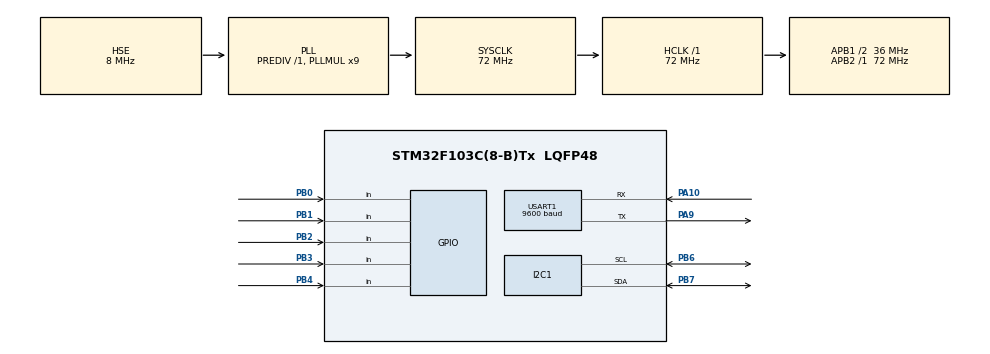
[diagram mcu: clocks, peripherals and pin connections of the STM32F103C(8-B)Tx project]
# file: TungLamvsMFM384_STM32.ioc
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FREERTOS.Mutexes01=mMeter,Dynamic,NULL,Available
FREERTOS.Queues01=qMeter,8,uint8_t,0,Dynamic,NULL,NULL
FREERTOS.Tasks01=rs485Task,1,768,StartDefaultTask,Default,NULL,Dynamic,NULL,NULL;touTask,0,512,StartTask02,Default,NULL,Dynamic,NULL,NULL;lcdTask,0,384,StartTask03,Default,NULL,Dynamic,NULL,NULL;uiTask,-2,384,StartTask04,Default,NULL,Dynamic,NULL,NULL;wdgTask,2,256,StartTask05,Default,NULL,Dynamic,NULL,NULL
FREERTOS.configTOTAL_HEAP_SIZE=20480
IWDG.Prescaler=IWDG_PRESCALER_64
IWDG.Reload=1250
Mcu.Family=STM32F1
Mcu.Name=STM32F103C(8-B)Tx
Mcu.Package=LQFP48
NVIC.PriorityGroup=NVIC_PRIORITYGROUP_4
NVIC.USART1_IRQn=true\:5\:0\:false\:false\:true\:true\:true\:true\:true
PA10.Mode=Asynchronous
PA10.Signal=USART1_RX
PA13.Mode=Serial_Wire
PA13.Signal=SYS_JTMS-SWDIO
PA14.Mode=Serial_Wire
PA14.Signal=SYS_JTCK-SWCLK
PA9.Mode=Asynchronous
PA9.Signal=USART1_TX
PB0.Signal=GPIO_Input
PB1.Signal=GPIO_Input
PB2.Signal=GPIO_Input
PB3.Signal=GPIO_Input
PB4.Signal=GPIO_Input
PB6.Mode=I2C
PB6.Signal=I2C1_SCL
PB7.Mode=I2C
PB7.Signal=I2C1_SDA
PC14-OSC32_IN.Mode=LSE-External-Oscillator
PC14-OSC32_IN.Signal=RCC_OSC32_IN
PC15-OSC32_OUT.Mode=LSE-External-Oscillator
PC15-OSC32_OUT.Signal=RCC_OSC32_OUT
PD0-OSC_IN.Mode=HSE-External-Oscillator
PD0-OSC_IN.Signal=RCC_OSC_IN
PD1-OSC_OUT.Mode=HSE-External-Oscillator
PD1-OSC_OUT.Signal=RCC_OSC_OUT
ProjectManager.HeapSize=0x200
ProjectManager.StackSize=0x400
ProjectManager.TargetToolchain=MDK-ARM V5.32
RCC.AHBFreq_Value=72000000
RCC.APB1CLKDivider=RCC_HCLK_DIV2
RCC.APB1Freq_Value=36000000
RCC.APB1TimFreq_Value=72000000
RCC.APB2Freq_Value=72000000
RCC.APB2TimFreq_Value=72000000
RCC.HCLKFreq_Value=72000000
RCC.PLLMUL=RCC_PLL_MUL9
RCC.PLLSourceVirtual=RCC_PLLSOURCE_HSE
RCC.SYSCLKFreq_VALUE=72000000
RCC.SYSCLKSource=RCC_SYSCLKSOURCE_PLLCLK
RCC.USBFreq_Value=72000000
RTC.Date=28
RTC.WeekDay=RTC_WEEKDAY_WEDNESDAY
RTC.Year=26
USART1.BaudRate=9600
USART1.Parity=PARITY_EVEN
USART1.VirtualMode=VM_ASYNC
VP_FREERTOS_VS_CMSIS_V1.Mode=CMSIS_V1
VP_IWDG_VS_IWDG.Mode=IWDG_Activate
VP_RTC_VS_RTC_Activate.Mode=RTC_Enabled
VP_RTC_VS_RTC_Calendar.Mode=RTC_Calendar
board=custom

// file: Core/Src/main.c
/* USER CODE BEGIN Header */
/**
  ******************************************************************************
  * @file           : main.c
  * @brief          : Main program body
  ******************************************************************************
  * @attention
  *
  * Copyright (c) 2026 STMicroelectronics.
  * All rights reserved.
  *
  * This software is licensed under terms that can be found in the LICENSE file
  * in the root directory of this software component.
  * If no LICENSE file comes with this software, it is provided AS-IS.
  *
  ******************************************************************************
  */
/* USER CODE END Header */
#include "main.h"
#include "cmsis_os.h"
#include "i2c.h"
#include "iwdg.h"
#include "rtc.h"
#include "usart.h"
#include "gpio.h"

void SystemClock_Config(void);
void MX_FREERTOS_Init(void);

int main(void)
{

  /* MCU Configuration--------------------------------------------------------*/

  /* Reset of all peripherals, Initializes the Flash interface and the Systick. */
  HAL_Init();

  /* Configure the system clock */
  SystemClock_Config();

  /* Initialize all configured peripherals */
  MX_GPIO_Init();
  MX_I2C1_Init();
  MX_IWDG_Init();
  MX_RTC_Init();
  MX_USART1_UART_Init();

  /* Call init function for freertos objects (in cmsis_os2.c) */
  MX_FREERTOS_Init();

  /* Start scheduler */
  osKernelStart();

  /* We should never get here as control is now taken by the scheduler */

  /* Infinite loop */
  while (1)
  {

  }
}

void SystemClock_Config(void)
{
  RCC_OscInitTypeDef RCC_OscInitStruct = {0};
  RCC_ClkInitTypeDef RCC_ClkInitStruct = {0};
  RCC_PeriphCLKInitTypeDef PeriphClkInit = {0};

  /** Initializes the RCC Oscillators according to the specified parameters
  * in the RCC_OscInitTypeDef structure.
  */
  RCC_OscInitStruct.OscillatorType = RCC_OSCILLATORTYPE_LSI|RCC_OSCILLATORTYPE_HSE;
  RCC_OscInitStruct.HSEState = RCC_HSE_ON;
  RCC_OscInitStruct.HSEPredivValue = RCC_HSE_PREDIV_DIV1;
  RCC_OscInitStruct.HSIState = RCC_HSI_ON;
  RCC_OscInitStruct.LSIState = RCC_LSI_ON;
  RCC_OscInitStruct.PLL.PLLState = RCC_PLL_ON;
  RCC_OscInitStruct.PLL.PLLSource = RCC_PLLSOURCE_HSE;
  RCC_OscInitStruct.PLL.PLLMUL = RCC_PLL_MUL9;
  if (HAL_RCC_OscConfig(&RCC_OscInitStruct) != HAL_OK)
  {
    Error_Handler();
  }

  /** Initializes the CPU, AHB and APB buses clocks
  */
  RCC_ClkInitStruct.ClockType = RCC_CLOCKTYPE_HCLK|RCC_CLOCKTYPE_SYSCLK
                              |RCC_CLOCKTYPE_PCLK1|RCC_CLOCKTYPE_PCLK2;
  RCC_ClkInitStruct.SYSCLKSource = RCC_SYSCLKSOURCE_PLLCLK;
  RCC_ClkInitStruct.AHBCLKDivider = RCC_SYSCLK_DIV1;
  RCC_ClkInitStruct.APB1CLKDivider = RCC_HCLK_DIV2;
  RCC_ClkInitStruct.APB2CLKDivider = RCC_HCLK_DIV1;

  if (HAL_RCC_ClockConfig(&RCC_ClkInitStruct, FLASH_LATENCY_2) != HAL_OK)
  {
    Error_Handler();
  }
  PeriphClkInit.PeriphClockSelection = RCC_PERIPHCLK_RTC;
  PeriphClkInit.RTCClockSelection = RCC_RTCCLKSOURCE_LSI;
  if (HAL_RCCEx_PeriphCLKConfig(&PeriphClkInit) != HAL_OK)
  {
    Error_Handler();
  }
}

void Error_Handler(void)
{
  __disable_irq();
  while (1)
  {
  }
}

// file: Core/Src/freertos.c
/* USER CODE BEGIN Header */
/**
  ******************************************************************************
  * File Name          : freertos.c
  * Description        : Code for freertos applications
  ******************************************************************************
  * @attention
  *
  * Copyright (c) 2026 STMicroelectronics.
  * All rights reserved.
  *
  * This software is licensed under terms that can be found in the LICENSE file
  * in the root directory of this software component.
  * If no LICENSE file comes with this software, it is provided AS-IS.
  *
  ******************************************************************************
  */
/* USER CODE END Header */

#include "FreeRTOS.h"
#include "task.h"
#include "main.h"
#include "cmsis_os.h"

/* USER CODE BEGIN Includes */
#include "tasks.h"
#include "app_main.h"

/* USER CODE END Includes */

osThreadId rs485TaskHandle;
osThreadId touTaskHandle;
osThreadId lcdTaskHandle;
osThreadId uiTaskHandle;
osThreadId wdgTaskHandle;
osMessageQId qMeterHandle;
osMutexId mMeterHandle;

void StartDefaultTask(void const * argument);
void StartTask02(void const * argument);
void StartTask03(void const * argument);
void StartTask04(void const * argument);
void StartTask05(void const * argument);

void MX_FREERTOS_Init(void); /* (MISRA C 2004 rule 8.1) */

/* GetIdleTaskMemory prototype (linked to static allocation support) */
void vApplicationGetIdleTaskMemory( StaticTask_t **ppxIdleTaskTCBBuffer, StackType_t **ppxIdleTaskStackBuffer, uint32_t *pulIdleTaskStackSize );

/* USER CODE BEGIN GET_IDLE_TASK_MEMORY */
static StaticTask_t xIdleTaskTCBBuffer;
static StackType_t xIdleStack[configMINIMAL_STACK_SIZE];

void vApplicationGetIdleTaskMemory( StaticTask_t **ppxIdleTaskTCBBuffer, StackType_t **ppxIdleTaskStackBuffer, uint32_t *pulIdleTaskStackSize )
{
  *ppxIdleTaskTCBBuffer = &xIdleTaskTCBBuffer;
  *ppxIdleTaskStackBuffer = &xIdleStack[0];
  *pulIdleTaskStackSize = configMINIMAL_STACK_SIZE;
  /* place for user code */
}
/* USER CODE END GET_IDLE_TASK_MEMORY */

void MX_FREERTOS_Init(void) {
  /* Create the mutex(es) */
  /* definition and creation of mMeter */
  osMutexDef(mMeter);
  mMeterHandle = osMutexCreate(osMutex(mMeter));

  /* Create the queue(s) */
  /* definition and creation of qMeter */
  osMessageQDef(qMeter, 8, uint8_t);
  qMeterHandle = osMessageCreate(osMessageQ(qMeter), NULL);

  /* USER CODE BEGIN RTOS_QUEUES */
  /* add queues, ... */
  app_main_init();
  /* USER CODE END RTOS_QUEUES */

  /* Create the thread(s) */
  /* definition and creation of rs485Task */
  osThreadDef(rs485Task, StartDefaultTask, osPriorityAboveNormal, 0, 768);
  rs485TaskHandle = osThreadCreate(osThread(rs485Task), NULL);

  /* definition and creation of touTask */
  osThreadDef(touTask, StartTask02, osPriorityNormal, 0, 512);
  touTaskHandle = osThreadCreate(osThread(touTask), NULL);

  /* definition and creation of lcdTask */
  osThreadDef(lcdTask, StartTask03, osPriorityNormal, 0, 384);
  lcdTaskHandle = osThreadCreate(osThread(lcdTask), NULL);

  /* definition and creation of uiTask */
  osThreadDef(uiTask, StartTask04, osPriorityLow, 0, 384);
  uiTaskHandle = osThreadCreate(osThread(uiTask), NULL);

  /* definition and creation of wdgTask */
  osThreadDef(wdgTask, StartTask05, osPriorityHigh, 0, 256);
  wdgTaskHandle = osThreadCreate(osThread(wdgTask), NULL);

}

void StartDefaultTask(void const * argument)
{
  /* USER CODE BEGIN StartDefaultTask */
  tasks_rs485(argument);
  /* USER CODE END StartDefaultTask */
}

void StartTask02(void const * argument)
{
  /* USER CODE BEGIN StartTask02 */
  tasks_tou(argument);
  /* USER CODE END StartTask02 */
}

void StartTask03(void const * argument)
{
  /* USER CODE BEGIN StartTask03 */
  tasks_lcd(argument);
  /* USER CODE END StartTask03 */
}

void StartTask04(void const * argument)
{
  /* USER CODE BEGIN StartTask04 */
  tasks_ui(argument);
  /* USER CODE END StartTask04 */
}

void StartTask05(void const * argument)
{
  /* USER CODE BEGIN StartTask05 */
  tasks_wdg(argument);
  /* USER CODE END StartTask05 */
}
